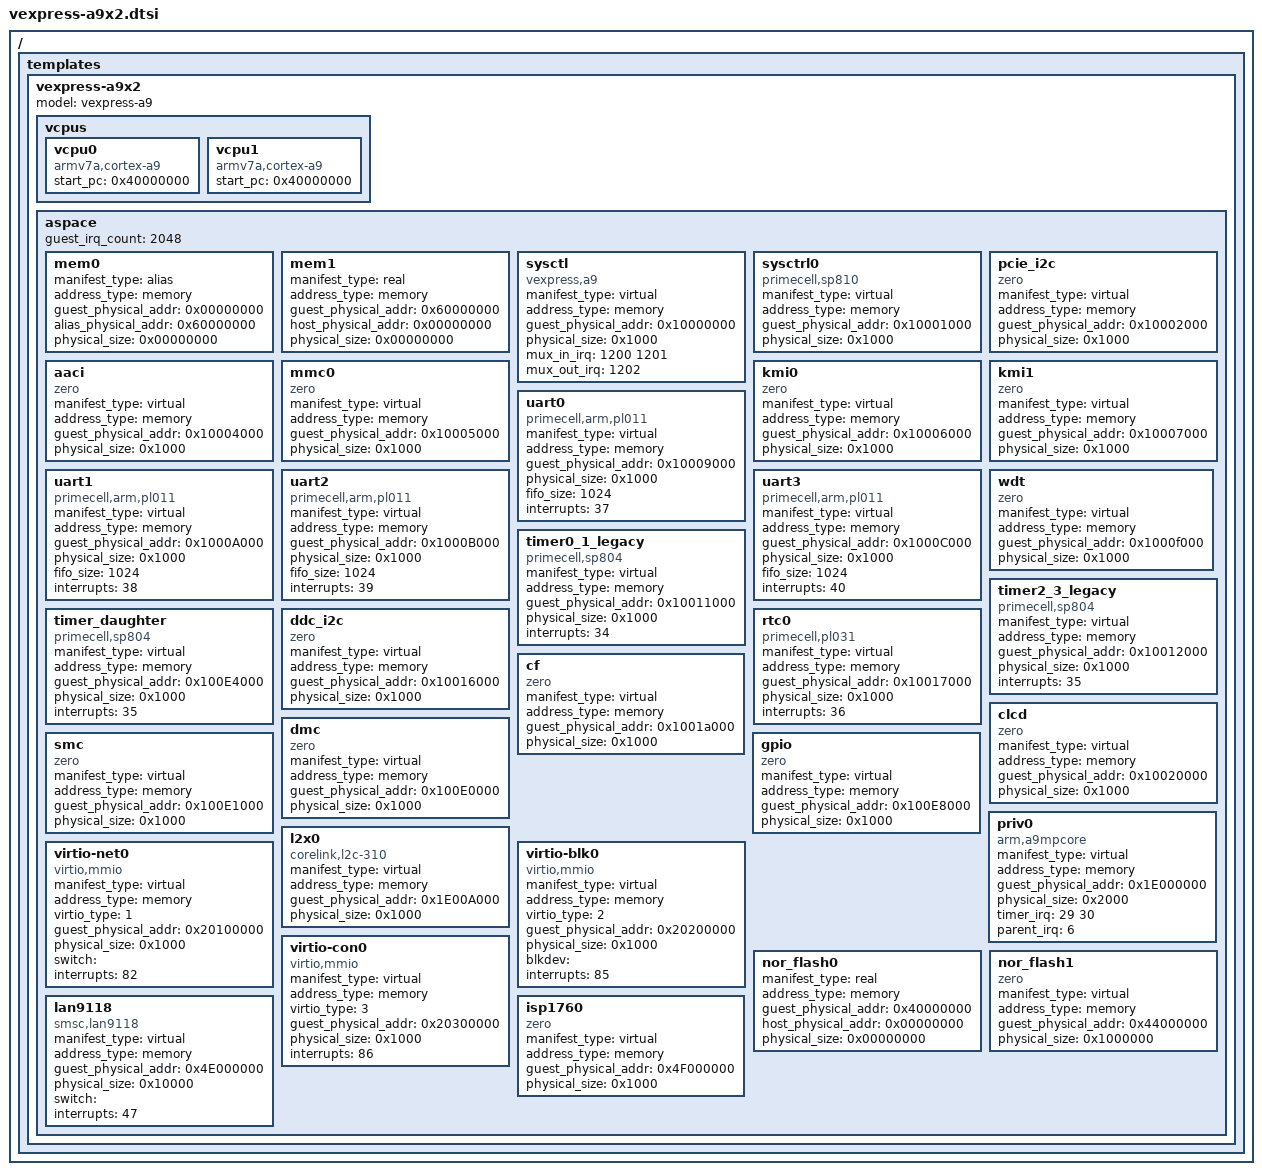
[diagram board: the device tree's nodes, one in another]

/ {
	templates {
		vexpress-a9x2 {
			model = "vexpress-a9";
			device_type = "guest";

			vcpus {
				vcpu0 {
					device_type = "vcpu";
					compatible = "armv7a,cortex-a9";
					start_pc = <0x40000000>;
				};

				vcpu1 {
					device_type = "vcpu";
					compatible = "armv7a,cortex-a9";
					start_pc = <0x40000000>;
				};
			};
			
			aspace {
				guest_irq_count = <2048>;

				/* Assume the REMAP region is mapped to DDR */
				mem0 {
					manifest_type = "alias";
					address_type = "memory";
					guest_physical_addr = <0x00000000>;
					alias_physical_addr = <0x60000000>;
					physical_size = <0x00000000>; /* To be set by DTS including this file */
					device_type = "ram";
				};

				mem1 {
					manifest_type = "real";
					address_type = "memory";
					guest_physical_addr = <0x60000000>;
					host_physical_addr = <0x00000000>; /* To be set by DTS including this file */
					physical_size = <0x00000000>; /* To be set by DTS including this file */
					device_type = "ram";
				};

				sysctl {
					manifest_type = "virtual";
					address_type = "memory";
					guest_physical_addr = <0x10000000>;
					physical_size = <0x1000>;
					device_type = "sys";
					compatible = "vexpress,a9";
					mux_in_irq = <1200 1201>;
					mux_out_irq = <1202>;
				};

				sysctrl0 {
					manifest_type = "virtual";
					address_type = "memory";
					guest_physical_addr = <0x10001000>;
					physical_size = <0x1000>;
					device_type = "sys";
					compatible = "primecell,sp810";
				};

				pcie_i2c { /* No I2C */
					manifest_type = "virtual";
					address_type = "memory";
					guest_physical_addr = <0x10002000>;
					physical_size = <0x1000>;
					device_type = "misc";
					compatible = "zero";
				};

				aaci { /* No Audio Controller */
					manifest_type = "virtual";
					address_type = "memory";
					guest_physical_addr = <0x10004000>;
					physical_size = <0x1000>;
					device_type = "misc";
					compatible = "zero";
				};

				mmc0 { /* No Multimedia Card Interface */
					manifest_type = "virtual";
					address_type = "memory";
					guest_physical_addr = <0x10005000>;
					physical_size = <0x1000>;
					device_type = "misc";
					compatible = "zero";
				};

				kmi0 { /* No Keyboard/Mouse Interface */
					manifest_type = "virtual";
					address_type = "memory";
					guest_physical_addr = <0x10006000>;
					physical_size = <0x1000>;
					device_type = "misc";
					compatible = "zero";
				};

				kmi1 { /* No Keyboard/Mouse Interface */
					manifest_type = "virtual";
					address_type = "memory";
					guest_physical_addr = <0x10007000>;
					physical_size = <0x1000>;
					device_type = "misc";
					compatible = "zero";
				};

				uart0 {
					manifest_type = "virtual";
					address_type = "memory";
					guest_physical_addr = <0x10009000>;
					physical_size = <0x1000>;
					device_type = "serial";
					compatible = "primecell,arm,pl011";
					fifo_size = <1024>;
					interrupts = <37>;
				};

				uart1 {
					manifest_type = "virtual";
					address_type = "memory";
					guest_physical_addr = <0x1000A000>;
					physical_size = <0x1000>;
					device_type = "serial";
					compatible = "primecell,arm,pl011";
					fifo_size = <1024>;
					interrupts = <38>;
				};

				uart2 {
					manifest_type = "virtual";
					address_type = "memory";
					guest_physical_addr = <0x1000B000>;
					physical_size = <0x1000>;
					device_type = "serial";
					compatible = "primecell,arm,pl011";
					fifo_size = <1024>;
					interrupts = <39>;
				};

				uart3 {
					manifest_type = "virtual";
					address_type = "memory";
					guest_physical_addr = <0x1000C000>;
					physical_size = <0x1000>;
					device_type = "serial";
					compatible = "primecell,arm,pl011";
					fifo_size = <1024>;
					interrupts = <40>;
				};

				wdt { /* No Watch-Dog controller */
					manifest_type = "virtual";
					address_type = "memory";
					guest_physical_addr = <0x1000f000>;
					physical_size = <0x1000>;
					device_type = "misc";
					compatible = "zero";
				};

				timer0_1_legacy {
					manifest_type = "virtual";
					address_type = "memory";
					guest_physical_addr = <0x10011000>;
					physical_size = <0x1000>;
					device_type = "timer";
					compatible = "primecell,sp804";
					interrupts = <34>;
				};

				timer2_3_legacy {
					manifest_type = "virtual";
					address_type = "memory";
					guest_physical_addr = <0x10012000>;
					physical_size = <0x1000>;
					device_type = "timer";
					compatible = "primecell,sp804";
					interrupts = <35>;
				};

				timer_daughter {
					manifest_type = "virtual";
					address_type = "memory";
					guest_physical_addr = <0x100E4000>;
					physical_size = <0x1000>;
					device_type = "timer";
					compatible = "primecell,sp804";
					interrupts = <35>;
				};

				ddc_i2c { /* No I2C */
					manifest_type = "virtual";
					address_type = "memory";
					guest_physical_addr = <0x10016000>;
					physical_size = <0x1000>;
					device_type = "misc";
					compatible = "zero";
				};

				rtc0 {
					manifest_type = "virtual";
					address_type = "memory";
					guest_physical_addr = <0x10017000>;
					physical_size = <0x1000>;
					device_type = "rtc";
					compatible = "primecell,pl031";
					interrupts = <36>;
				};

				cf { /* No PATA Controller */
					manifest_type = "virtual";
					address_type = "memory";
					guest_physical_addr = <0x1001a000>;
					physical_size = <0x1000>;
					device_type = "misc";
					compatible = "zero";
				};

				clcd { /* No Color LCD */
					manifest_type = "virtual";
					address_type = "memory";
					guest_physical_addr = <0x10020000>;
					physical_size = <0x1000>;
					device_type = "misc";
					compatible = "zero";
				};

				dmc { /* No DMC */
					manifest_type = "virtual";
					address_type = "memory";
					guest_physical_addr = <0x100E0000>;
					physical_size = <0x1000>;
					device_type = "misc";
					compatible = "zero";
				};

				smc { /* No SMC */
					manifest_type = "virtual";
					address_type = "memory";
					guest_physical_addr = <0x100E1000>;
					physical_size = <0x1000>;
					device_type = "misc";
					compatible = "zero";
				};

				gpio { /* No GPIO */
					manifest_type = "virtual";
					address_type = "memory";
					guest_physical_addr = <0x100E8000>;
					physical_size = <0x1000>;
					device_type = "misc";
					compatible = "zero";
				};

				priv0 {
					manifest_type = "virtual";
					address_type = "memory";
					guest_physical_addr = <0x1E000000>;
					physical_size = <0x2000>;
					device_type = "misc";
					compatible = "arm,a9mpcore";
					timer_irq = <29 30>;
					parent_irq = <6>;
				};

				l2x0 {
					manifest_type = "virtual";
					address_type = "memory";
					guest_physical_addr = <0x1E00A000>;
					physical_size = <0x1000>;
					device_type = "cache";
					compatible = "corelink,l2c-310";
				};

				virtio-net0 {
					manifest_type = "virtual";
					address_type = "memory";
					device_type = "virtio";
					compatible = "virtio,mmio";
					virtio_type = <1>;
					guest_physical_addr = <0x20100000>;
					physical_size = <0x1000>;
					switch = ""; /* To be set by DTS including this file */
					interrupts = <82>;
				};

				virtio-blk0 {
					manifest_type = "virtual";
					address_type = "memory";
					device_type = "virtio";
					compatible = "virtio,mmio";
					virtio_type = <2>;
					guest_physical_addr = <0x20200000>;
					physical_size = <0x1000>;
					blkdev = ""; /* To be set by DTS including this file */
					interrupts = <85>;
				};

				virtio-con0 {
					manifest_type = "virtual";
					address_type = "memory";
					device_type = "virtio";
					compatible = "virtio,mmio";
					virtio_type = <3>;
					guest_physical_addr = <0x20300000>;
					physical_size = <0x1000>;
					interrupts = <86>;
				};

				nor_flash0 {
					manifest_type = "real";
					address_type = "memory";
					guest_physical_addr = <0x40000000>;
					host_physical_addr = <0x00000000>; /* To be set by DTS including this file */
					physical_size = <0x00000000>; /* To be set by DTS including this file */
					device_type = "rom";
				};

				nor_flash1 { /* No Second NOR flash */
					manifest_type = "virtual";
					address_type = "memory";
					guest_physical_addr = <0x44000000>;
					physical_size = <0x1000000>; /* 16 MB */
					device_type = "misc";
					compatible = "zero";
				};

				lan9118 { /* Ethernet Controller */
					manifest_type = "virtual";
					address_type = "memory";
					guest_physical_addr = <0x4E000000>;
					physical_size = <0x10000>;
					device_type = "nic";
					compatible = "smsc,lan9118";
					switch = ""; /* To be set by DTS including this file */
					interrupts = <47>;
				};

				isp1760 { /* No USB Controller */
					manifest_type = "virtual";
					address_type = "memory";
					guest_physical_addr = <0x4F000000>;
					physical_size = <0x1000>;
					device_type = "misc";
					compatible = "zero";
				};
			};
		};
	};
};
